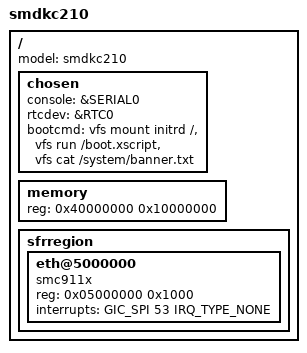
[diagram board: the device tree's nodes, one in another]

/dts-v1/;

#include "./exynos4210.dtsi"

/ {
	model = "smdkc210";

	chosen {
		console = &SERIAL0;
		rtcdev = &RTC0;
	};

	memory {
		device_type = "memory";
		reg = <0x40000000 0x10000000>; /* 256 MB */
	};

	chosen {
		bootcmd = /* Mount initrd device */
			  "vfs mount initrd /",

			  /* Run boot script */
			  "vfs run /boot.xscript",

			  /* Print banner */
			  "vfs cat /system/banner.txt";
	};

	sfrregion {
		eth@5000000 {
			compatible = "smc911x";
			reg = <0x05000000 0x1000>;
			interrupts = <GIC_SPI 53 IRQ_TYPE_NONE>;
		};
	};
};
